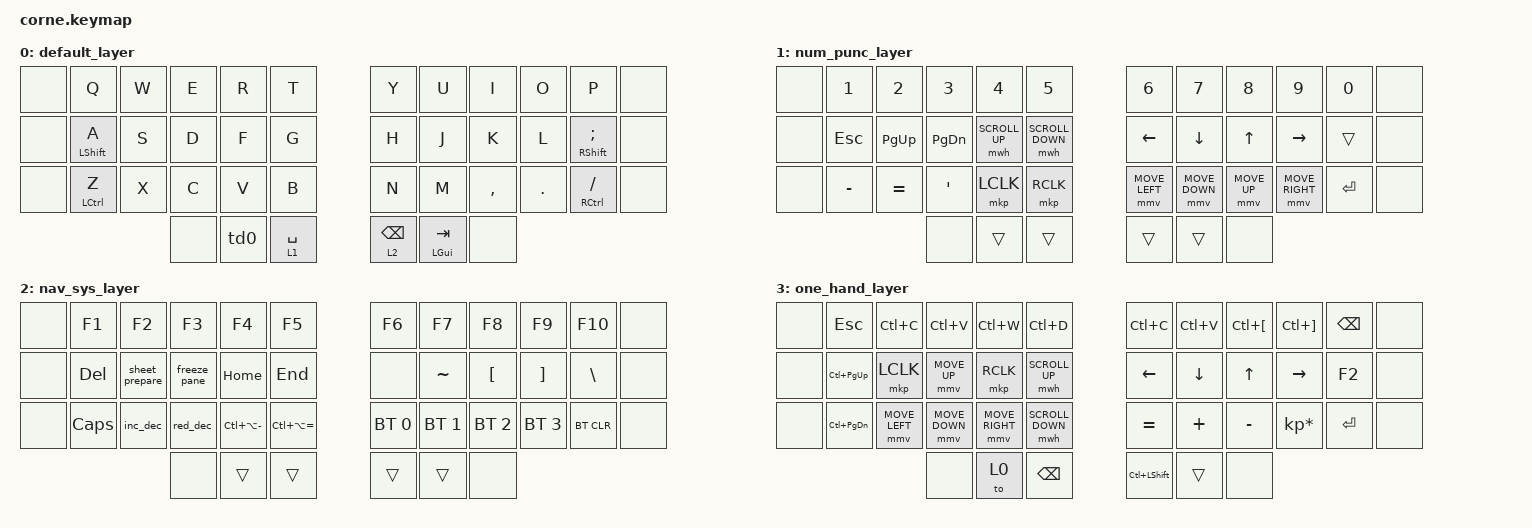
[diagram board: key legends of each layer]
/*
 * Copyright (c) 2020 The ZMK Contributors
 *
 * SPDX-License-Identifier: MIT
 */

#include <behaviors.dtsi>
#include <dt-bindings/zmk/bt.h>
#include <dt-bindings/zmk/keys.h>
#include <dt-bindings/zmk/outputs.h>
#include <dt-bindings/zmk/mouse.h>

// adjust mouse movement speed

#define U_MOUSE_MOVE_MAX 2000                     /* <--- New max speed setting (default: 600) */
#undef MOVE_UP
#undef MOVE_DOWN
#undef MOVE_LEFT
#undef MOVE_RIGHT
#define MOVE_UP MOVE_VERT(-U_MOUSE_MOVE_MAX)
#define MOVE_DOWN MOVE_VERT(U_MOUSE_MOVE_MAX)
#define MOVE_LEFT MOVE_HOR(-U_MOUSE_MOVE_MAX)
#define MOVE_RIGHT MOVE_HOR(U_MOUSE_MOVE_MAX)

// adjust mouse scroll wheel speed

#define U_MOUSE_SCROLL_MAX 20                    /* <--- New max speed setting (default: 10) */

#undef SCROLL_UP
#undef SCROLL_DOWN
#undef SCROLL_LEFT
#undef SCROLL_RIGHT
#define SCROLL_UP SCROLL_VERT(U_MOUSE_SCROLL_MAX)
#define SCROLL_DOWN SCROLL_VERT(-U_MOUSE_SCROLL_MAX)
#define SCROLL_LEFT SCROLL_HOR(-U_MOUSE_SCROLL_MAX)
#define SCROLL_RIGHT SCROLL_HOR(U_MOUSE_SCROLL_MAX)

&mmv {
    time-to-max-speed-ms = <400>;             /* <--- How long time until max speed is reached (default: 500) */
};
    
&mwh {
    time-to-max-speed-ms = <500>;             /* <--- How long time until max speed is reached */
};

&mt {
    flavor = "tap-preferred";
};

/ {
    behaviors {
        td0: tap_dance {
            compatible = "zmk,behavior-tap-dance";
            label = "TAP_DANCE_0";
            #binding-cells = <0>;
            tapping-term-ms = <250>;
            bindings = <&kp LALT>, <&tog 3>;
        };
    };

    keymap {

        // Key location reference
        //     0            1            2            3            4            5                  6            7            8            9           10           11
        //    12           13           14           15           16           17                 18           19           20           21           22           23
        //    24           25           26           27           28           29                 30           31           32           33           34           35
        //                                           36           37           38                 39           40           41

        compatible = "zmk,keymap";
        // Layer 0
        default_layer {

            bindings = <
&none       &kp Q               &kp W      &kp E      &kp R      &kp T               &kp Y      &kp U         &kp I         &kp O           &kp P               &none
&none       &mt LSHFT A         &kp S      &kp D      &kp F      &kp G               &kp H      &kp J         &kp K         &kp L           &mt RSHFT SEMI      &none
&none       &mt LCTRL Z         &kp X      &kp C      &kp V      &kp B               &kp N      &kp M         &kp COMMA     &kp DOT         &mt RCTRL FSLH      &none
                                    &none       &td0       &lt 1 SPACE               &lt 2 BSPC       &mt LGUI TAB      &none
            >;
        };
        // Layer 1
        num_punc_layer {

            bindings = <
&none       &kp N1     &kp N2     &kp N3     &kp N4          &kp N5                     &kp N6          &kp N7          &kp N8        &kp N9           &kp N0       &none
&none       &kp ESC    &kp PG_UP  &kp PG_DN  &mwh SCROLL_UP  &mwh SCROLL_DOWN           &kp LEFT        &kp DOWN        &kp UP        &kp RIGHT        &trans       &none
&none       &kp MINUS  &kp EQUAL  &kp SQT    &mkp LCLK       &mkp RCLK                  &mmv MOVE_LEFT  &mmv MOVE_DOWN  &mmv MOVE_UP  &mmv MOVE_RIGHT  &kp ENTER    &none
                                  &none      &trans          &trans                     &trans          &trans          &none
            >;
        };
        // Layer 2
        nav_sys_layer {

            bindings = <
&none   &kp F1        &kp F2              &kp F3            &kp F4                  &kp F5                     &kp F6          &kp F7         &kp F8         &kp F9         &kp F10         &none
&none   &kp DEL       &sheet_prepare      &freeze_pane      &kp HOME                &kp END                    &none           &kp TILDE      &kp LBKT       &kp RBKT       &kp BSLH        &none
&none   &kp CAPS      &inc_dec            &red_dec          &kp LC(LA(MINUS))       &kp LC(LA(EQUAL))          &bt BT_SEL 0    &bt BT_SEL 1   &bt BT_SEL 2   &bt BT_SEL 3   &bt BT_CLR      &none
                                          &none             &trans                  &trans                     &trans          &trans         &none
            >;
        };
        // Layer 3
        one_hand_layer {

            bindings = <
&none   &kp ESC             &kp LC(C)          &kp LC(V)         &kp LC(W)         &kp LC(D)                 &kp LC(C)       &kp LC(V)       &kp LC(LBKT)         &kp LC(RBKT)            &kp BSPC      &none
&none   &kp LC(PG_UP)       &mkp LCLK          &mmv MOVE_UP      &mkp RCLK         &mwh SCROLL_UP            &kp LEFT        &kp DOWN        &kp UP               &kp RIGHT               &kp F2        &none
&none   &kp LC(PG_DN)       &mmv MOVE_LEFT     &mmv MOVE_DOWN    &mmv MOVE_RIGHT   &mwh SCROLL_DOWN          &kp EQUAL       &kp PLUS        &kp MINUS            &kp KP_MULTIPLY         &kp ENTER     &none
                                               &none             &to 0             &kp BSPC                  &kp LC(LSHFT)      &trans       &none
            >;
        };
    };

    combos {
        compatible = "zmk,combos";
        
        combo_divide {
            timeout-ms = <50>;
            key-positions = <31 32>;
            layers = <3>;
            bindings = <&kp KP_DIVIDE>;
        };

        combo_middle_click {
            timeout-ms = <50>;
            key-positions = <14 16>;
            layers = <3>;
            bindings = <&mkp MCLK>;
        };

        combo_scroll_left {
            timeout-ms = <50>;
            key-positions = <13 25>;
            layers = <3>;
            bindings = <&mwh SCROLL_LEFT>;
        };

        combo_scroll_right {
            timeout-ms = <50>;
            key-positions = <17 29>;
            layers = <3>;
            bindings = <&mwh SCROLL_RIGHT>;
        };
    };

    macros {
        // EXCEL: prepare formatting of the sheet with favorite font, gridline and font size
        sheet_prepare: sheet_prepare {
            label = "ZM_sheet_prepare";
            compatible = "zmk,behavior-macro";
            #binding-cells = <0>;
            wait-ms = <50>;
            tap-ms = <50>;
            bindings 
                // select whole sheet
                = <&kp LC(A)>
                // font selection
                , <&kp LALT &kp H &kp F &kp F &kp A &kp R &kp I &kp A &kp L &kp SPACE &kp N &kp A &kp R &kp R &kp O &kp W &kp ENTER>
                // remove gridline
                , <&kp LALT &kp W &kp V &kp G>
                // font size
                , <&kp LALT &kp H &kp F &kp S &kp N1 &kp N1 &kp ENTER>
                ;
        };

        // EXCEL: select the cell and choose place to turn on freeze pane, activate again to remove freeze pane
        freeze_pane: freeze_pane {
            label = "ZM_freeze_pane";
            compatible = "zmk,behavior-macro";
            #binding-cells = <0>;
            wait-ms = <30>;
            tap-ms = <40>;
            bindings = <&kp LALT &kp W &kp F &kp F>;
        };

        // EXCEL: increase decimal points
        inc_dec: inc_dec {
            label = "ZM_inc_dec";
            compatible = "zmk,behavior-macro";
            #binding-cells = <0>;
            wait-ms = <30>;
            tap-ms = <40>;
            bindings = <&kp LALT &kp H &kp N0>;
        };

        // EXCEL: reduce decimal points
        red_dec: red_dec {
            label = "ZM_red_dec";
            compatible = "zmk,behavior-macro";
            #binding-cells = <0>;
            wait-ms = <30>;
            tap-ms = <40>;
            bindings = <&kp LALT &kp H &kp N9>;
        };
    };

};
